# STM32G0B0 register map
File version: 1.6
CPU: CM0 r0p1, little endian, MPU, no FPU, 2 interrupt priority bits
Registers are 32-bit, read-write, reset 0x0 unless marked. A register's access mark holds for its fields unless they carry their own. Offsets are from the block's base; [hi:lo] are bit positions; {n}, {i} and the like mark numbered series; 'fields as' and 'values as' point back to an identical list.

## EXTI — External interrupt/event controller
Base 0x40021800
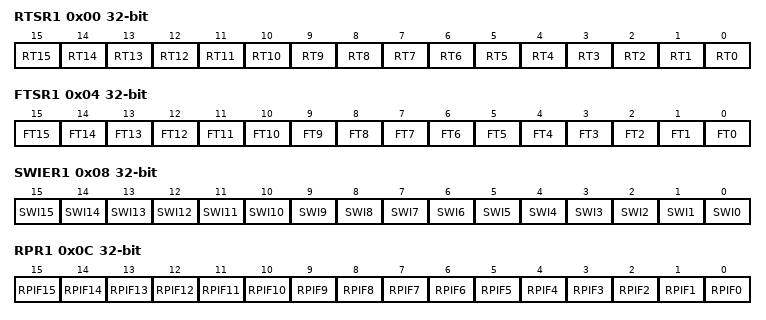
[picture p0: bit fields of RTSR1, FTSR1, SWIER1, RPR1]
0x00 RTSR1 — EXTI rising trigger selection register
  [all] fields
    0=Disabled (Rising edge trigger is disabled); 1=Enabled (Rising edge trigger is enabled)
  [n] RT{n} (n=0..15) — Rising trigger event configuration bit of Configurable Event line
0x04 FTSR1 — EXTI falling trigger selection register
  [all] fields
    0=Disabled (Falling edge trigger is disabled); 1=Enabled (Falling edge trigger is enabled)
  [n] FT{n} (n=0..15) — Falling trigger event configuration bit of configurable line
0x08 SWIER1 — EXTI software interrupt event register
  [all] fields
    on write: 1=Pend (Generates an interrupt request)
  [n] SWI{n} (n=0..15) — Software rising edge event trigger on line
0x0C RPR1 — EXTI rising edge pending register
  [all] fields
    on read: 0=NotPending (No trigger request occurred); 1=Pending (Selected trigger request occurred) | on write: 1=Clears pending bit
  [n] RPIF{n} write-1-clears (n=6..15) — Rising edge event pending for configurable line
  [5] RPIF5 write-1-clears — configurable event inputs x rising edge Pending bit
  [n] RPIF{n} write-1-clears (n=0..4) — Rising edge event pending for configurable line
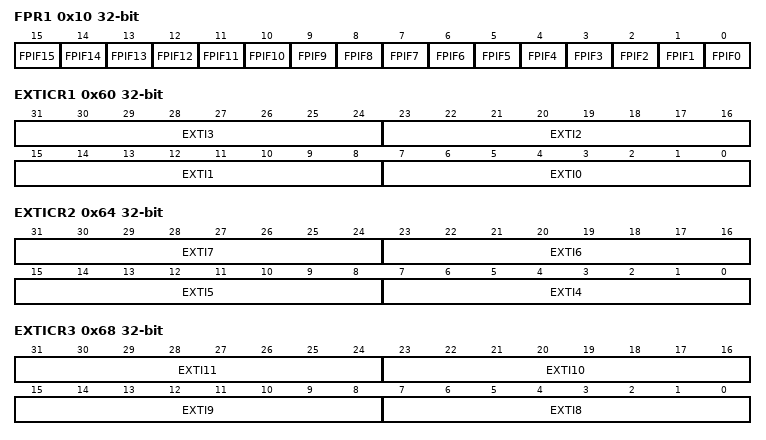
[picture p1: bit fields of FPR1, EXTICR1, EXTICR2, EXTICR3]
0x10 FPR1 — EXTI falling edge pending register
  [all] fields
    values as the fields of RPR1
  [n] FPIF{n} write-1-clears (n=0..15) — Falling edge event pending for configurable line
0x60 EXTICR1 — EXTI external interrupt selection register
  [all] fields
    0=PA (Select PAx as the source input for the EXTIx external interrupt); 1=PB (Select PBx as the source input for the EXTIx external interrupt); 2=PC (Select PCx as the source input for the EXTIx external interrupt); 3=PD (Select PDx as the source input for the EXTIx external interrupt); 5=PF (Select PFx as the source input for the EXTIx external interrupt)
  [8n+7:8n] EXTI{n} (n=0..3) — GPIO port selection
0x64 EXTICR2 — EXTI external interrupt selection register
  [all] fields
    values as the fields of EXTICR1
  [8n-25:8n-32] EXTI{n} (n=4..7) — GPIO port selection
0x68 EXTICR3 — EXTI external interrupt selection register
  [all] fields
    values as the fields of EXTICR1
  [8n-57:8n-64] EXTI{n} (n=8..11) — GPIO port selection
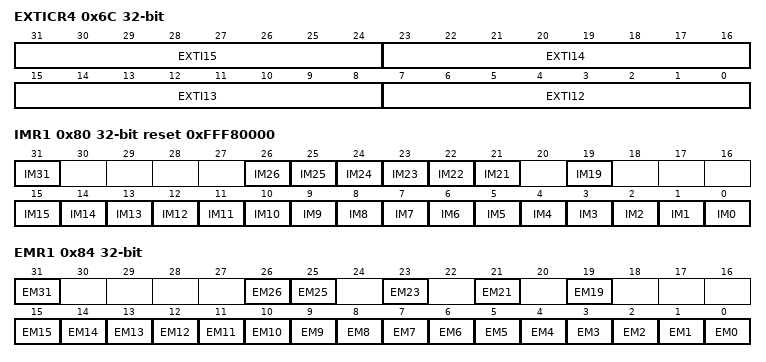
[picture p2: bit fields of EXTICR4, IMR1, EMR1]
0x6C EXTICR4 — EXTI external interrupt selection register
  [all] fields
    values as the fields of EXTICR1
  [8n-89:8n-96] EXTI{n} (n=12..15) — GPIO port selection
0x80 IMR1 reset 0xFFF80000 — EXTI CPU wakeup with interrupt mask register
  [all] fields
    0=Masked (Interrupt request line is masked); 1=Unmasked (Interrupt request line is unmasked)
  [31] IM31 — CPU wakeup with interrupt mask on event input
  [n] IM{n} (n=21..26) — CPU wakeup with interrupt mask on event input
  [19] IM19 — CPU wakeup with interrupt mask on event input
  [n] IM{n} (n=0..15) — CPU wakeup with interrupt mask on event input
0x84 EMR1 (alternate view of IMR1) — EXTI CPU wakeup with event mask register
  [all] fields
    0=Masked (Event request line is masked); 1=Unmasked (Event request line is unmasked)
  [31] EM31 — CPU wakeup with event mask on event input
  [26] EM26 — CPU wakeup with event mask on event input
  [25] EM25 — CPU wakeup with event mask on event input
  [23] EM23 — CPU wakeup with event mask on event input
  [21] EM21 — CPU wakeup with event mask on event input
  [19] EM19 — CPU wakeup with event mask on event input
  [n] EM{n} (n=0..15) — CPU wakeup with event mask on event input

## FLASH
Base 0x40022000
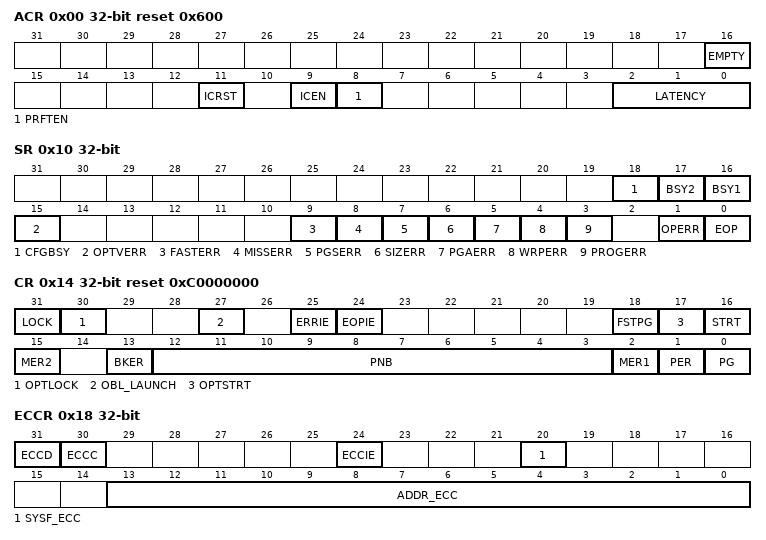
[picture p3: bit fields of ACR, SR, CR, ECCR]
0x00 ACR reset 0x600 — Access control register
  [16] EMPTY — Flash User area empty
  [11] ICRST — Instruction cache reset
  [9] ICEN — Instruction cache enable
  [8] PRFTEN — Prefetch enable
  [2:0] LATENCY
0x08 KEYR wo — Flash key register
  [31:0] KEY — KEYR
0x0C OPTKEYR wo — Option byte key register
  [31:0] OPTKEY — Option byte key
0x10 SR — Status register
  [18] CFGBSY — Programming or erase configuration busy.
  [17] BSY2
  [16] BSY1
  [15] OPTVERR — Option and Engineering bits loading validity error
  [9] FASTERR — Fast programming error
  [8] MISSERR — Fast programming data miss error
  [7] PGSERR — Programming sequence error
  [6] SIZERR — Size error
  [5] PGAERR — Programming alignment error
  [4] WRPERR — Write protected error
  [3] PROGERR — Programming error
  [1] OPERR — Operation error
  [0] EOP — End of operation
0x14 CR reset 0xC0000000 — Flash control register
  [31] LOCK — FLASH_CR Lock
  [30] OPTLOCK — Options Lock
  [27] OBL_LAUNCH — Force the option byte loading
  [25] ERRIE — Error interrupt enable
  [24] EOPIE — End of operation interrupt enable
  [18] FSTPG — Fast programming
  [17] OPTSTRT — Options modification start
  [16] STRT — Start
  [15] MER2
  [13] BKER
  [12:3] PNB — Page number
  [2] MER1 — Mass erase
  [1] PER — Page erase
  [0] PG — Programming
0x18 ECCR access per field — Flash ECC register
  [31] ECCD rw — ECC detection
  [30] ECCC rw — ECC correction
  [24] ECCIE rw — ECC correction interrupt enable
  [20] SYSF_ECC ro — ECC fail for Corrected ECC Error or Double ECC Error in info block
  [13:0] ADDR_ECC ro — ECC fail address
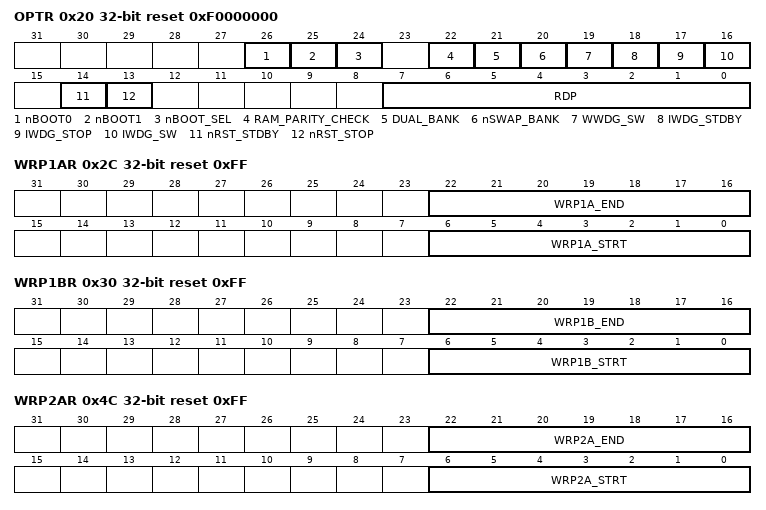
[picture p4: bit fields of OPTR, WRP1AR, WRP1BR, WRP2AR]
0x20 OPTR reset 0xF0000000 — Flash option register
  [26] nBOOT0 — nBOOT0 option bit
  [25] nBOOT1 — Boot configuration
  [24] nBOOT_SEL
  [22] RAM_PARITY_CHECK — SRAM parity check control
  [21] DUAL_BANK
  [20] nSWAP_BANK
  [19] WWDG_SW — Window watchdog selection
  [18] IWDG_STDBY — Independent watchdog counter freeze in Standby mode
  [17] IWDG_STOP — Independent watchdog counter freeze in Stop mode
  [16] IWDG_SW — Independent watchdog selection
  [14] nRST_STDBY
  [13] nRST_STOP
  [7:0] RDP — Read protection level
0x2C WRP1AR reset 0xFF — Flash WRP area A address register
  [22:16] WRP1A_END — WRP area A end offset
  [6:0] WRP1A_STRT — WRP area A start offset
0x30 WRP1BR reset 0xFF — Flash WRP area B address register
  [22:16] WRP1B_END — WRP area B end offset
  [6:0] WRP1B_STRT — WRP area B start offset
0x4C WRP2AR reset 0xFF — FLASH WRP2 area A address register
  [22:16] WRP2A_END, [6:0] WRP2A_STRT
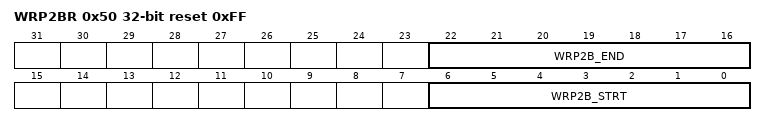
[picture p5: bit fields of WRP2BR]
0x50 WRP2BR reset 0xFF — FLASH WRP2 area B address register
  [22:16] WRP2B_END, [6:0] WRP2B_STRT
